# STM32L4P5 register map
File version: 1.8
CPU: CM4 r0p1, little endian, MPU, FPU, 4 interrupt priority bits
Registers are 32-bit, read-write, reset 0x0 unless marked. A register's access mark holds for its fields unless they carry their own. Offsets are from the block's base; [hi:lo] are bit positions.

## USART1 (part 1 of 2) — Universal synchronous asynchronous receiver transmitter
Base 0x40013800
Same registers: USART2 0x40004400, USART3 0x40004800, UART4 0x40004C00, UART5 0x40005000
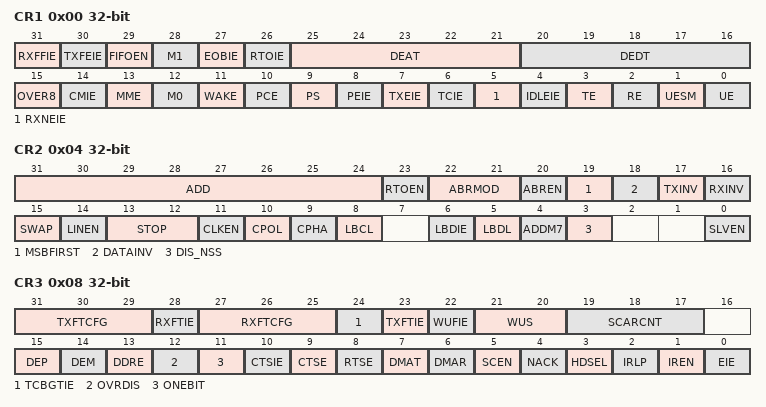
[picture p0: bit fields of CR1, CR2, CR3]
0x00 CR1 — USART control register 1
  [31] RXFFIE — RXFIFO full interrupt enable This bit is set and cleared by software.
    0=Disabled (Interrupt inhibited); 1=Enabled (USART interrupt generated when RXFF = 1 in the USART_ISR register)
  [30] TXFEIE — TXFIFO empty interrupt enable This bit is set and cleared by software.
    0=Disabled (Interrupt inhibited); 1=Enabled (USART interrupt generated when TXFE = 1 in the USART_ISR register)
  [29] FIFOEN — FIFO mode enable This bit is set and cleared by software. This bitfield can only be written when the USART is disabled (UE = 0). Note: FIFO mode can be used on standard UART communication, in SPI master/slave mode and in Smartcard modes only. It must not be enabled in IrDA and LIN modes.
    0=Disabled (FIFO mode is disabled); 1=Enabled (FIFO mode is enabled)
  [28] M1 — Word length This bit must be used in conjunction with bit 12 (M0) to determine the word length. It is set or cleared by software. M[1:0] = 00 : 1 start bit, 8 Data bits, n Stop bit M[1:0] = 01 : 1 start bit, 9 Data bits, n Stop bit M[1:0] = 10 : 1 start bit, 7 Data bits, n Stop bit This bit can only be written when the USART is disabled (UE = 0). Note: In 7-bits data length mode, the Smartcard mode, LIN master mode and auto baud rate (0x7F and 0x55 frames detection) are not supported.
    0=M0 (Use M0 to set the data bits); 1=Bit7 (1 start bit, 7 data bits, n stop bits)
  [27] EOBIE — End-of-block interrupt enable This bit is set and cleared by software. Note: If the USART does not support Smartcard mode, this bit is reserved and must be kept at reset value. Refer to Section 33.4: USART implementation on page 1038.
    0=Disabled (Interrupt is inhibited); 1=Enabled (A USART interrupt is generated when the EOBF flag is set in the ISR register)
  [26] RTOIE — Receiver timeout interrupt enable This bit is set and cleared by software. Note: If the USART does not support the Receiver timeout feature, this bit is reserved and must be kept at reset value. Section 33.4: USART implementation on page 1038.
    0=Disabled (Interrupt is inhibited); 1=Enabled (An USART interrupt is generated when the RTOF bit is set in the ISR register)
  [25:21] DEAT — Driver enable assertion time This 5-bit value defines the time between the activation of the DE (Driver Enable) signal and the beginning of the start bit. It is expressed in sample time units (1/8 or 1/16 bit time, depending on the oversampling rate). This bitfield can only be written when the USART is disabled (UE = 0). Note: If the Driver Enable feature is not supported, this bit is reserved and must be kept at reset value. Refer to Section 33.4: USART implementation on page 1038.
  [20:16] DEDT — Driver enable deassertion time This 5-bit value defines the time between the end of the last stop bit, in a transmitted message, and the de-activation of the DE (Driver Enable) signal. It is expressed in sample time units (1/8 or 1/16 bit time, depending on the oversampling rate). If the USART_TDR register is written during the DEDT time, the new data is transmitted only when the DEDT and DEAT times have both elapsed. This bitfield can only be written when the USART is disabled (UE = 0). Note: If the Driver Enable feature is not supported, this bit is reserved and must be kept at reset value. Refer to Section 33.4: USART implementation on page 1038.
  [15] OVER8 — Oversampling mode This bit can only be written when the USART is disabled (UE = 0). Note: In LIN, IrDA and Smartcard modes, this bit must be kept cleared.
    0=Oversampling16 (Oversampling by 16); 1=Oversampling8 (Oversampling by 8)
  [14] CMIE — Character match interrupt enable This bit is set and cleared by software.
    0=Disabled (Interrupt is disabled); 1=Enabled (Interrupt is generated when the CMF bit is set in the ISR register)
  [13] MME — Mute mode enable This bit enables the USART Mute mode function. When set, the USART can switch between active and Mute mode, as defined by the WAKE bit. It is set and cleared by software.
    0=Disabled (Receiver in active mode permanently); 1=Enabled (Receiver can switch between mute mode and active mode)
  [12] M0 — Word length This bit is used in conjunction with bit 28 (M1) to determine the word length. It is set or cleared by software (refer to bit 28 (M1)description). This bit can only be written when the USART is disabled (UE = 0).
    0=Bit8 (1 start bit, 8 data bits, n stop bits); 1=Bit9 (1 start bit, 9 data bits, n stop bits)
  [11] WAKE — Receiver wakeup method This bit determines the USART wakeup method from Mute mode. It is set or cleared by software. This bitfield can only be written when the USART is disabled (UE = 0).
    0=Idle line; 1=Address mask
  [10] PCE — Parity control enable This bit selects the hardware parity control (generation and detection). When the parity control is enabled, the computed parity is inserted at the MSB position (9th bit if M = 1; 8th bit if M = 0) and the parity is checked on the received data. This bit is set and cleared by software. Once it is set, PCE is active after the current byte (in reception and in transmission). This bitfield can only be written when the USART is disabled (UE = 0).
    0=Disabled (Parity control disabled); 1=Enabled (Parity control enabled)
  [9] PS — Parity selection This bit selects the odd or even parity when the parity generation/detection is enabled (PCE bit set). It is set and cleared by software. The parity is selected after the current byte. This bitfield can only be written when the USART is disabled (UE = 0).
    0=Even parity; 1=Odd (Odd parity)
  [8] PEIE — PE interrupt enable This bit is set and cleared by software.
    0=Disabled (Interrupt is disabled); 1=Enabled (Interrupt is generated whenever PE=1 in the ISR register)
  [7] TXEIE — TXFIFO not-full interrupt enable This bit is set and cleared by software.
    0=Disabled (Interrupt is disabled); 1=Enabled (Interrupt is generated whenever TXE=1 in the ISR register)
  [6] TCIE — Transmission complete interrupt enable This bit is set and cleared by software.
    0=Disabled (Interrupt is disabled); 1=Enabled (Interrupt is generated whenever TC=1 in the ISR register)
  [5] RXNEIE — RXFIFO not empty interrupt enable This bit is set and cleared by software.
    0=Disabled (Interrupt is disabled); 1=Enabled (Interrupt is generated whenever ORE=1 or RXNE=1 in the ISR register)
  [4] IDLEIE — IDLE interrupt enable This bit is set and cleared by software.
    0=Disabled (Interrupt is disabled); 1=Enabled (Interrupt is generated whenever IDLE=1 in the ISR register)
  [3] TE — Transmitter enable This bit enables the transmitter. It is set and cleared by software. Note: During transmission, a low pulse on the TE bit ( 0 followed by 1 ) sends a preamble (idle line) after the current word, except in Smartcard mode. In order to generate an idle character, the TE must not be immediately written to 1 . To ensure the required duration, the software can poll the TEACK bit in the USART_ISR register. Note: In Smartcard mode, when TE is set, there is a 1 bit-time delay before the transmission starts.
    0=Disabled (Transmitter is disabled); 1=Enabled (Transmitter is enabled)
  [2] RE — Receiver enable This bit enables the receiver. It is set and cleared by software.
    0=Disabled (Receiver is disabled); 1=Enabled (Receiver is enabled)
  [1] UESM — USART enable in low-power mode When this bit is cleared, the USART cannot wake up the MCU from low-power mode. When this bit is set, the USART can wake up the MCU from low-power mode. This bit is set and cleared by software. Note: It is recommended to set the UESM bit just before entering low-power mode and clear it when exit from low-power mode. Note: If the USART does not support the wakeup from Stop feature, this bit is reserved and must be kept at reset value. Refer to Section 33.4: USART implementation on page 1038.
    0=Disabled (USART not able to wake up the MCU from Stop mode); 1=Enabled (USART able to wake up the MCU from Stop mode)
  [0] UE — USART enable When this bit is cleared, the USART prescalers and outputs are stopped immediately, and all current operations are discarded. The USART configuration is kept, but all the USART_ISR status flags are reset. This bit is set and cleared by software. Note: To enter low-power mode without generating errors on the line, the TE bit must be previously reset and the software must wait for the TC bit in the USART_ISR to be set before resetting the UE bit. Note: The DMA requests are also reset when UE = 0 so the DMA channel must be disabled before resetting the UE bit. Note: In Smartcard mode, (SCEN = 1), the CK is always available when CLKEN = 1, regardless of the UE bit value.
    0=Disabled (UART is disabled); 1=Enabled (UART is enabled)
0x04 CR2 — USART control register 2
  [31:24] ADD — Address of the USART node These bits give the address of the USART node in Mute mode or a character code to be recognized in low-power or Run mode: In Mute mode: they are used in multiprocessor communication to wakeup from Mute mode with 4-bit/7-bit address mark detection. The MSB of the character sent by the transmitter should be equal to 1. In 4-bit address mark detection, only ADD[3:0] bits are used. In low-power mode: they are used for wake up from low-power mode on character match. When WUS[1:0] is programmed to 0b00 (WUF active on address match), the wakeup from low-power mode is performed when the received character corresponds to the character programmed through ADD[6:0] or ADD[3:0] bitfield (depending on ADDM7 bit), and WUF interrupt is enabled by setting WUFIE bit. The MSB of the character sent by transmitter should be equal to 1. In Run mode with Mute mode inactive (for example, end-of-block detection in ModBus protocol): the whole received character (8 bits) is compared to ADD[7:0] value and CMF flag is set on match. An interrupt is generated if the CMIE bit is set. These bits can only be written when the reception is disabled (RE = 0) or when the USART is disabled (UE = 0).
  [23] RTOEN — Receiver timeout enable This bit is set and cleared by software. When this feature is enabled, the RTOF flag in the USART_ISR register is set if the RX line is idle (no reception) for the duration programmed in the RTOR (receiver timeout register). Note: If the USART does not support the Receiver timeout feature, this bit is reserved and must be kept at reset value. Refer to Section 33.4: USART implementation on page 1038.
    0=Disabled (Receiver timeout feature disabled); 1=Enabled (Receiver timeout feature enabled)
  [22:21] ABRMOD — Auto baud rate mode These bits are set and cleared by software. This bitfield can only be written when ABREN = 0 or the USART is disabled (UE = 0). Note: If DATAINV = 1 and/or MSBFIRST = 1 the patterns must be the same on the line, for example 0xAA for MSBFIRST) Note: If the USART does not support the auto baud rate feature, this bit is reserved and must be kept at reset value. Refer to Section 33.4: USART implementation on page 1038.
    0=Start (Measurement of the start bit is used to detect the baud rate); 1=Edge (Falling edge to falling edge measurement); 2=Frame7F (0x7F frame detection); 3=Frame55 (0x55 frame detection)
  [20] ABREN — Auto baud rate enable This bit is set and cleared by software. Note: If the USART does not support the auto baud rate feature, this bit is reserved and must be kept at reset value. Refer to Section 33.4: USART implementation on page 1038.
    0=Disabled (Auto baud rate detection is disabled); 1=Enabled (Auto baud rate detection is enabled)
  [19] MSBFIRST — Most significant bit first This bit is set and cleared by software. This bitfield can only be written when the USART is disabled (UE = 0).
    0=LSB (data is transmitted/received with data bit 0 first, following the start bit); 1=MSB (data is transmitted/received with MSB (bit 7/8/9) first, following the start bit)
  [18] DATAINV — Binary data inversion This bit is set and cleared by software. This bitfield can only be written when the USART is disabled (UE = 0).
    0=Positive (Logical data from the data register are send/received in positive/direct logic); 1=Negative (Logical data from the data register are send/received in negative/inverse logic)
  [17] TXINV — TX pin active level inversion This bit is set and cleared by software. This enables the use of an external inverter on the TX line. This bitfield can only be written when the USART is disabled (UE = 0).
    0=Standard (TX pin signal works using the standard logic levels); 1=Inverted (TX pin signal values are inverted)
  [16] RXINV — RX pin active level inversion This bit is set and cleared by software. This enables the use of an external inverter on the RX line. This bitfield can only be written when the USART is disabled (UE = 0).
    0=Standard (RX pin signal works using the standard logic levels); 1=Inverted (RX pin signal values are inverted)
  [15] SWAP — Swap TX/RX pins This bit is set and cleared by software. This bitfield can only be written when the USART is disabled (UE = 0).
    0=Standard (TX/RX pins are used as defined in standard pinout); 1=Swapped (The TX and RX pins functions are swapped)
  [14] LINEN — LIN mode enable This bit is set and cleared by software. The LIN mode enables the capability to send LIN synchronous breaks (13 low bits) using the SBKRQ bit in the USART_CR1 register, and to detect LIN Sync breaks. This bitfield can only be written when the USART is disabled (UE = 0). Note: If the USART does not support LIN mode, this bit is reserved and must be kept at reset value. Refer to Section 33.4: USART implementation on page 1038.
    0=Disabled (LIN mode disabled); 1=Enabled (LIN mode enabled)
  [13:12] STOP — Stop bits These bits are used for programming the stop bits. This bitfield can only be written when the USART is disabled (UE = 0).
    0=1 stop bit; 1=Stop0p5 (0.5 stop bit); 2=2 stop bit; 3=Stop1p5 (1.5 stop bit)
  [11] CLKEN — Clock enable This bit enables the user to enable the CK pin. This bit can only be written when the USART is disabled (UE = 0). Note: If neither synchronous mode nor Smartcard mode is supported, this bit is reserved and must be kept at reset value. Refer to Section 33.4: USART implementation on page 1038. In Smartcard mode, in order to provide correctly the CK clock to the smartcard, the steps below must be respected: UE = 0 SCEN = 1 GTPR configuration CLKEN= 1 Note: UE = 1
    0=Disabled (CK pin disabled); 1=Enabled (CK pin enabled)
  [10] CPOL — Clock polarity This bit enables the user to select the polarity of the clock output on the CK pin in synchronous mode. It works in conjunction with the CPHA bit to produce the desired clock/data relationship This bit can only be written when the USART is disabled (UE = 0). Note: If synchronous mode is not supported, this bit is reserved and must be kept at reset value. Refer to Section 33.4: USART implementation on page 1038.
    0=Low (Steady low value on CK pin outside transmission window); 1=High (Steady high value on CK pin outside transmission window)
  [9] CPHA — Clock phase This bit is used to select the phase of the clock output on the CK pin in synchronous mode. It works in conjunction with the CPOL bit to produce the desired clock/data relationship (see Figure 326 and Figure 327) This bit can only be written when the USART is disabled (UE = 0). Note: If synchronous mode is not supported, this bit is reserved and must be kept at reset value. Refer to Section 33.4: USART implementation on page 1038.
    0=First (The first clock transition is the first data capture edge); 1=Second (The second clock transition is the first data capture edge)
  [8] LBCL — Last bit clock pulse This bit is used to select whether the clock pulse associated with the last data bit transmitted (MSB) has to be output on the CK pin in synchronous mode. The last bit is the 7th or 8th or 9th data bit transmitted depending on the 7 or 8 or 9 bit format selected by the M bit in the USART_CR1 register. This bit can only be written when the USART is disabled (UE = 0). Note: If synchronous mode is not supported, this bit is reserved and must be kept at reset value. Refer to Section 33.4: USART implementation on page 1038.
    0=NotOutput (The clock pulse of the last data bit is not output to the CK pin); 1=Output (The clock pulse of the last data bit is output to the CK pin)
  [6] LBDIE — LIN break detection interrupt enable Break interrupt mask (break detection using break delimiter). Note: If LIN mode is not supported, this bit is reserved and must be kept at reset value. Refer to Section 33.4: USART implementation on page 1038.
    0=Disabled (Interrupt is inhibited); 1=Enabled (An interrupt is generated whenever LBDF=1 in the ISR register)
  [5] LBDL — LIN break detection length This bit is for selection between 11 bit or 10 bit break detection. This bit can only be written when the USART is disabled (UE = 0). Note: If LIN mode is not supported, this bit is reserved and must be kept at reset value. Refer to Section 33.4: USART implementation on page 1038.
    0=Bit10 (10-bit break detection); 1=Bit11 (11-bit break detection)
  [4] ADDM7 — 7-bit address detection/4-bit address detection This bit is for selection between 4-bit address detection or 7-bit address detection. This bit can only be written when the USART is disabled (UE = 0) Note: In 7-bit and 9-bit data modes, the address detection is done on 6-bit and 8-bit address (ADD[5:0] and ADD[7:0]) respectively.
    0=Bit4 (4-bit address detection); 1=Bit7 (7-bit address detection)
  [3] DIS_NSS — NSS pin enable When the DIS_NSS bit is set, the NSS pin input is ignored. Note: When SPI slave mode is not supported, this bit is reserved and must be kept at reset value. Refer to Section 33.4: USART implementation on page 1038.
    0=Disabled (SPI slave selection depends on NSS input pin); 1=Enabled (SPI slave is always selected and NSS input pin is ignored)
  [0] SLVEN — Synchronous Slave mode enable When the SLVEN bit is set, the synchronous slave mode is enabled. Note: When SPI slave mode is not supported, this bit is reserved and must be kept at reset value. Refer to Section 33.4: USART implementation on page 1038.
    0=Disabled (Slave mode disabled); 1=Enabled (Slave mode enabled)
0x08 CR3 — USART control register 3
  [31:29] TXFTCFG — TXFIFO threshold configuration Remaining combinations: Reserved
    0=Depth_1_8 (TXFIFO reaches 1/8 of its depth); 1=Depth_1_4 (TXFIFO reaches 1/4 of its depth); 2=Depth_1_2 (TXFIFO reaches 1/2 of its depth); 3=Depth_3_4 (TXFIFO reaches 3/4 of its depth); 4=Depth_7_8 (TXFIFO reaches 7/8 of its depth); 5=Empty (TXFIFO becomes empty)
  [28] RXFTIE — RXFIFO threshold interrupt enable This bit is set and cleared by software.
    0=Disabled (Interrupt inhibited); 1=Enabled (USART interrupt generated when Receive FIFO reaches the threshold programmed in RXFTCFG)
  [27:25] RXFTCFG — Receive FIFO threshold configuration Remaining combinations: Reserved
    0=Depth_1_8 (RXFIFO reaches 1/8 of its depth); 1=Depth_1_4 (RXFIFO reaches 1/4 of its depth); 2=Depth_1_2 (RXFIFO reaches 1/2 of its depth); 3=Depth_3_4 (RXFIFO reaches 3/4 of its depth); 4=Depth_7_8 (RXFIFO reaches 7/8 of its depth); 5=Full (RXFIFO becomes full)
  [24] TCBGTIE — Transmission complete before guard time, interrupt enable This bit is set and cleared by software. Note: If the USART does not support the Smartcard mode, this bit is reserved and must be kept at reset value. Refer to Section 33.4: USART implementation on page 1038.
    0=Disabled (Interrupt inhibited); 1=Enabled (USART interrupt generated whenever TCBGT=1 in the USART_ISR register)
  [23] TXFTIE — TXFIFO threshold interrupt enable This bit is set and cleared by software.
    0=Disabled (Interrupt inhibited); 1=Enabled (USART interrupt generated when Transmit FIFO reaches the threshold programmed in TXFTCFG)
  [22] WUFIE — Wakeup from low-power mode interrupt enable This bit is set and cleared by software. Note: WUFIE must be set before entering in low-power mode. Note: If the USART does not support the wakeup from Stop feature, this bit is reserved and must be kept at reset value. Refer to Section 33.4: USART implementation on page 1038.
    0=Disabled (Interrupt is inhibited); 1=Enabled (An USART interrupt is generated whenever WUF=1 in the ISR register)
  [21:20] WUS — Wakeup from low-power mode interrupt flag selection This bitfield specifies the event which activates the WUF (Wakeup from low-power mode flag). This bitfield can only be written when the USART is disabled (UE = 0). Note: If the USART does not support the wakeup from Stop feature, this bit is reserved and must be kept at reset value. Refer to Section 33.4: USART implementation on page 1038.
    0=Address (WUF active on address match); 2=Start (WuF active on Start bit detection); 3=RXNE (WUF active on RXNE)
  [19:17] SCARCNT — Smartcard auto-retry count This bitfield specifies the number of retries for transmission and reception in Smartcard mode. In transmission mode, it specifies the number of automatic retransmission retries, before generating a transmission error (FE bit set). In reception mode, it specifies the number or erroneous reception trials, before generating a reception error (RXNE/RXFNE and PE bits set). This bitfield must be programmed only when the USART is disabled (UE = 0). When the USART is enabled (UE = 1), this bitfield may only be written to 0x0, in order to stop retransmission. 0x1 to 0x7: number of automatic retransmission attempts (before signaling error) Note: If Smartcard mode is not supported, this bit is reserved and must be kept at reset value. Refer to Section 33.4: USART implementation on page 1038.
  [15] DEP — Driver enable polarity selection This bit can only be written when the USART is disabled (UE = 0). Note: If the Driver Enable feature is not supported, this bit is reserved and must be kept at reset value. Refer to Section 33.4: USART implementation on page 1038.
    0=High (DE signal is active high); 1=Low (DE signal is active low)
  [14] DEM — Driver enable mode This bit enables the user to activate the external transceiver control, through the DE signal. This bit can only be written when the USART is disabled (UE = 0). Note: If the Driver Enable feature is not supported, this bit is reserved and must be kept at reset value. Section 33.4: USART implementation on page 1038.
    0=Disabled (DE function is disabled); 1=Enabled (The DE signal is output on the RTS pin)
  [13] DDRE — DMA Disable on reception error This bit can only be written when the USART is disabled (UE=0). Note: The reception errors are: parity error, framing error or noise error.
    0=NotDisabled (DMA is not disabled in case of reception error); 1=Disabled (DMA is disabled following a reception error)
  [12] OVRDIS — Overrun disable This bit is used to disable the receive overrun detection. the ORE flag is not set and the new received data overwrites the previous content of the USART_RDR register. When FIFO mode is enabled, the RXFIFO is bypassed and data is written directly in USART_RDR register. Even when FIFO management is enabled, the RXNE flag is to be used. This bit can only be written when the USART is disabled (UE = 0). Note: This control bit enables checking the communication flow w/o reading the data
    0=Enabled (Overrun Error Flag, ORE, is set when received data is not read before receiving new data); 1=Disabled (Overrun functionality is disabled. If new data is received while the RXNE flag is still set the ORE flag is not set and the new received data overwrites the previous content of the RDR register)
  [11] ONEBIT — One sample bit method enable This bit enables the user to select the sample method. When the one sample bit method is selected the noise detection flag (NE) is disabled. This bit can only be written when the USART is disabled (UE = 0).
    0=Sample3 (Three sample bit method); 1=Sample1 (One sample bit method)
  [10] CTSIE — CTS interrupt enable Note: If the hardware flow control feature is not supported, this bit is reserved and must be kept at reset value. Refer to Section 33.4: USART implementation on page 1038.
    0=Disabled (Interrupt is inhibited); 1=Enabled (An interrupt is generated whenever CTSIF=1 in the ISR register)
  [9] CTSE — CTS enable This bit can only be written when the USART is disabled (UE = 0) Note: If the hardware flow control feature is not supported, this bit is reserved and must be kept at reset value. Refer to Section 33.4: USART implementation on page 1038.
    0=Disabled (CTS hardware flow control disabled); 1=Enabled (CTS mode enabled, data is only transmitted when the CTS input is asserted)
  [8] RTSE — RTS enable This bit can only be written when the USART is disabled (UE = 0). Note: If the hardware flow control feature is not supported, this bit is reserved and must be kept at reset value. Refer to Section 33.4: USART implementation on page 1038.
    0=Disabled (RTS hardware flow control disabled); 1=Enabled (RTS output enabled, data is only requested when there is space in the receive buffer)
  [7] DMAT — DMA enable transmitter This bit is set/reset by software
    0=Disabled (DMA mode is disabled for transmission); 1=Enabled (DMA mode is enabled for transmission)
  [6] DMAR — DMA enable receiver This bit is set/reset by software
    0=Disabled (DMA mode is disabled for reception); 1=Enabled (DMA mode is enabled for reception)
  [5] SCEN — Smartcard mode enable This bit is used for enabling Smartcard mode. This bitfield can only be written when the USART is disabled (UE = 0). Note: If the USART does not support Smartcard mode, this bit is reserved and must be kept at reset value. Refer to Section 33.4: USART implementation on page 1038.
    0=Disabled (Smartcard Mode disabled); 1=Enabled (Smartcard Mode enabled)
  [4] NACK — Smartcard NACK enable This bitfield can only be written when the USART is disabled (UE = 0). Note: If the USART does not support Smartcard mode, this bit is reserved and must be kept at reset value. Refer to Section 33.4: USART implementation on page 1038.
    0=Disabled (NACK transmission in case of parity error is disabled); 1=Enabled (NACK transmission during parity error is enabled)
  [3] HDSEL — Half-duplex selection Selection of Single-wire Half-duplex mode This bit can only be written when the USART is disabled (UE = 0).
    0=NotSelected (Half duplex mode is not selected); 1=Selected (Half duplex mode is selected)
  [2] IRLP — IrDA low-power This bit is used for selecting between normal and low-power IrDA modes This bit can only be written when the USART is disabled (UE = 0). Note: If IrDA mode is not supported, this bit is reserved and must be kept at reset value. Refer to Section 33.4: USART implementation on page 1038.
    0=Normal mode; 1=Low-power mode
  [1] IREN — IrDA mode enable This bit is set and cleared by software. This bit can only be written when the USART is disabled (UE = 0). Note: If IrDA mode is not supported, this bit is reserved and must be kept at reset value. Refer to Section 33.4: USART implementation on page 1038.
    0=Disabled (IrDA disabled); 1=Enabled (IrDA enabled)
  [0] EIE — Error interrupt enable Error Interrupt Enable Bit is required to enable interrupt generation in case of a framing error, overrun error noise flag or SPI slave underrun error (FE = 1 or ORE = 1 or NE = 1 or UDR = 1 in the USART_ISR register).
    0=Disabled (Interrupt is inhibited); 1=Enabled (An interrupt is generated when FE=1 or ORE=1 or NF=1 in the ISR register)
